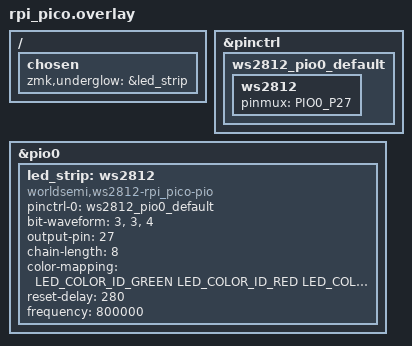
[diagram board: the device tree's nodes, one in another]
#include <dt-bindings/led/led.h>

&pinctrl {
	ws2812_pio0_default: ws2812_pio0_default {
		ws2812 {
			pinmux = <PIO0_P27>;
		};
	};
};

&pio0 {
	status = "okay";

	led_strip: ws2812 {
		compatible = "worldsemi,ws2812-rpi_pico-pio";
		status = "okay";
		pinctrl-0 = <&ws2812_pio0_default>;
		pinctrl-names = "default";
		bit-waveform = <3>, <3>, <4>;

		output-pin = <27>;
		chain-length = <8>;
		color-mapping = <LED_COLOR_ID_GREEN
				 LED_COLOR_ID_RED
				 LED_COLOR_ID_BLUE>;
		reset-delay = <280>;
		frequency = <800000>;
	};
};

/ {
    chosen {
        zmk,underglow = &led_strip;
    };
};
